// Sample LIN Description File (LDF) -- Easy-LIN test fixture
// Conforms to LIN 2.1 specification

LIN_description_file ;
LIN_protocol_version = "2.1" ;
LIN_language_version = "2.1" ;
LIN_speed = 19.2 kbps ;
Channel_name = "DB" ;

Nodes {
  Master: VehicleMaster, 5 ms, 0.1 ms ;
  Slaves: MotorController, LightController, SensorNode ;
}

Signals {
  // Motor controller signals
  MotorSpeed: 8, 0, VehicleMaster, MotorController ;
  MotorDirection: 2, 0, VehicleMaster, MotorController ;
  MotorEnable: 1, 0, VehicleMaster, MotorController ;
  MotorFeedback: 8, 0, MotorController, VehicleMaster ;
  MotorStatus: 4, 0, MotorController, VehicleMaster ;

  // Light controller signals
  LightLevel: 8, 0, VehicleMaster, LightController ;
  LightMode: 3, 0, VehicleMaster, LightController ;
  LightStatus: 2, 0, LightController, VehicleMaster ;

  // Sensor signals
  Temperature: 10, 0, SensorNode, VehicleMaster ;
  Humidity: 8, 0, SensorNode, VehicleMaster ;
  SensorError: 1, 0, SensorNode, VehicleMaster ;
}

Frames {
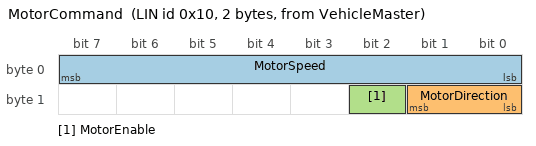
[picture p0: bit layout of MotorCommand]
  MotorCommand : 0x10, VehicleMaster, 2 {
    MotorSpeed, 0 ;
    MotorDirection, 8 ;
    MotorEnable, 10 ;
  }
  MotorResponse : 0x11, MotorController, 2 {
    MotorFeedback, 0 ;
    MotorStatus, 8 ;
  }
  LightCommand : 0x20, VehicleMaster, 1 {
    LightLevel, 0 ;
    LightMode, 8 ;
  }
  LightResponse : 0x21, LightController, 1 {
    LightStatus, 0 ;
  }
  SensorData : 0x30, SensorNode, 2 {
    Temperature, 0 ;
    Humidity, 10 ;
    SensorError, 18 ;
  }
}

Schedule_tables {
  NormalSchedule {
    MotorCommand delay 10 ms ;
    MotorResponse delay 10 ms ;
    LightCommand delay 10 ms ;
    LightResponse delay 10 ms ;
    SensorData delay 20 ms ;
  }
  FastSchedule {
    MotorCommand delay 5 ms ;
    MotorResponse delay 5 ms ;
    SensorData delay 10 ms ;
  }
}

Signal_encoding_types {
  MotorDirectionEncoding {
    logical_value, 0, "Forward" ;
    logical_value, 1, "Reverse" ;
    logical_value, 2, "Brake" ;
    logical_value, 3, "Coast" ;
  }
  TemperatureEncoding {
    physical_value, 0, 1023, 0.25, -40.0, "deg C" ;
  }
  LightModeEncoding {
    logical_value, 0, "Off" ;
    logical_value, 1, "Low" ;
    logical_value, 2, "Medium" ;
    logical_value, 3, "High" ;
    logical_value, 4, "Auto" ;
  }
}

Signal_representation {
  MotorDirectionEncoding: MotorDirection ;
  TemperatureEncoding: Temperature ;
  LightModeEncoding: LightMode ;
}

Node_attributes {
  MotorController {
    LIN_protocol = "2.1" ;
    configured_NAD = 0x01 ;
    initial_NAD = 0x01 ;
    product_id = 0x1234, 0x0001, 0x00 ;
    response_error = MotorStatus ;
    P2_min = 50 ms ;
    ST_min = 0 ms ;
    N_As_timeout = 1000 ms ;
    N_Cr_timeout = 1000 ms ;
    configurable_frames {
      MotorCommand ;
      MotorResponse ;
    }
  }
  LightController {
    LIN_protocol = "2.1" ;
    configured_NAD = 0x02 ;
    initial_NAD = 0x02 ;
    product_id = 0x1234, 0x0002, 0x00 ;
    response_error = LightStatus ;
    configurable_frames {
      LightCommand ;
      LightResponse ;
    }
  }
  SensorNode {
    LIN_protocol = "2.0" ;
    configured_NAD = 0x03 ;
    initial_NAD = 0x03 ;
    product_id = 0x5678, 0x0001, 0x01 ;
    response_error = SensorError ;
    configurable_frames {
      SensorData ;
    }
  }
}
